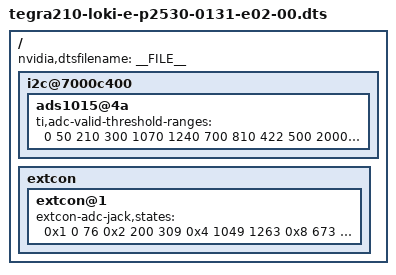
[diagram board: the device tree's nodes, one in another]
/*
 * arch/arm64/boot/dts/tegra210-loki-e-p2530-0131-e02-00.dts
 *
 * Copyright (c) 2014, NVIDIA CORPORATION.  All rights reserved.
 *
 * This program is free software; you can redistribute it and/or modify
 * it under the terms of the GNU General Public License as published by
 * the Free Software Foundation; version 2 of the License.
 *
 * This program is distributed in the hope that it will be useful, but WITHOUT
 * ANY WARRANTY; without even the implied warranty of MERCHANTABILITY or
 * FITNESS FOR A PARTICULAR PURPOSE.  See the GNU General Public License for
 * more details.
 *
 * You should have received a copy of the GNU General Public License along
 * with this program; if not, write to the Free Software Foundation, Inc.,
 * 51 Franklin Street, Fifth Floor, Boston, MA  02110-1301, USA.
 *
 */

#include "tegra210-loki-e-p2530-0131-e01-00.dts"
#include "tegra210-platforms/tegra210-loki-rail-delay-p2530-0999-e02.dtsi"

/ {
	nvidia,dtsfilename = __FILE__;

	i2c@7000c400 {
		ads1015@4a {
			ti,adc-valid-threshold-ranges= <0     50
							210   300
							1070  1240
							700   810
							422   500
							2000  2047>;
		};
	};
	extcon {
		extcon@1 {
			extcon-adc-jack,states = <0x1    0     76
						  0x2    200   309
						  0x4    1049  1263
						  0x8    673   848
						  0x10   402   524>;
		};
	};
};
